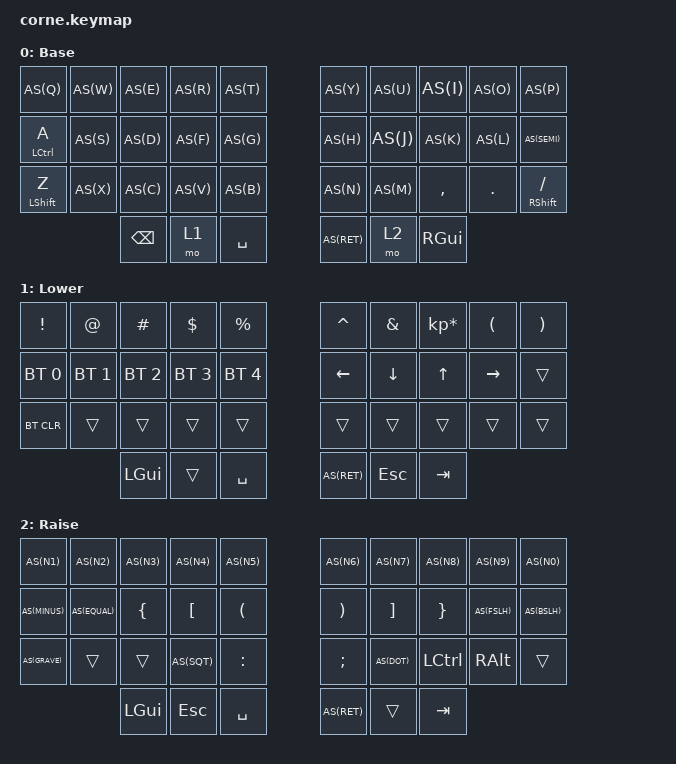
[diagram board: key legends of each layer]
/*
 * Copyright (c) 2020 The ZMK Contributors
 *
 * SPDX-License-Identifier: MIT
 */

#include <behaviors.dtsi>
#include <dt-bindings/zmk/keys.h>
#include <dt-bindings/zmk/bt.h>


#define AS(keycode) &kp keycode

/ {
    chosen {
      zmk,matrix_transform = &five_column_transform;
    };

    behaviors {
        bhm: balanced_homerow_mods {
            compatible = "zmk,behavior-hold-tap";
            #binding-cells = <2>;
            tapping-term-ms = <800>;    // <---[[moderate duration]]
            quick-tap-ms = <0>;
            flavor = "balanced";
            bindings = <&kp>, <&kp>;
        };
    };
        keymap {
                compatible = "zmk,keymap";

                default_layer {
// -----------------------------------------------------------------------------------------
// |  Q  |  W  |  E   |  R  |  T  |     |  Y  |  U   |  I   |  O   | P |
// |  A  |  S  |  D   |  F  |  G  |     |  H  |  J   |  K   |  L   | ' | 
// |  Z  |  X  |  C   |  V  |  B  |     |  N  |  M   | CTRL | META | . |
//             | BSPC | LWR | SPC |     | ENT | RSE  | GUI  |
                        display-name = "Base";
                        bindings = <
   AS(Q) AS(W) AS(E) AS(R) AS(T)     AS(Y)   AS(U)  AS(I)     AS(O)     AS(P)
   &bhm LCTRL A AS(S) AS(D) AS(F) AS(G)     AS(H)   AS(J)  AS(K)     AS(L)     AS(SEMI)
   &bhm LSHIFT Z AS(X) AS(C) AS(V) AS(B)     AS(N)   AS(M)  &kp COMMA  &kp DOT &bhm RSHIFT FSLH 
        &kp BSPC &mo 1 &kp SPACE     AS(RET) &mo 2  &kp RGUI
                        >;
                };

                lower_layer {
// -----------------------------------------------------------------------------------------
// | !     |  @  |  #  |  $  |  %  |     |  ^  |  &  |  *  |  (  |  )  |
// | BT1   | BT2 | BT3 | BT4 | BT5 |     | LFT | DWN |  UP | RGT |     |
// | BTCLR |     |     |     |     |     |     |     |     |     |     |
//               | GUI |     | SPC |     | ENT | ESC | TAB |
                        display-name = "Lower";
                        bindings = <
   &kp EXCL     &kp AT       &kp HASH     &kp DLLR     &kp PRCNT        &kp CARET &kp AMPS  &kp KP_MULTIPLY &kp LPAR  &kp RPAR
   &bt BT_SEL 0 &bt BT_SEL 1 &bt BT_SEL 2 &bt BT_SEL 3 &bt BT_SEL 4     &kp LEFT  &kp DOWN  &kp UP          &kp RIGHT &trans 
   &bt BT_CLR   &trans       &trans       &trans       &trans           &trans    &trans    &trans          &trans    &trans 
                             &kp LGUI     &trans       &kp SPACE        AS(RET)   &kp ESC   &kp TAB
                        >;
                };

                raise_layer {
// -----------------------------------------------------------------------------------------
// | 1! |  2@ |  3# |  4$ |  5% |     |  6^ |  7& |  8* |  9(  |  0)  |
// | -_ |  =+ |  {  |  [  |  (  |     |  )  |  ]  |  }  |  /?  |  \|  |
// | `~ |     |     |  '" |  :  |     |  ;  |  .> | CTRL| META |      |
//            | GUI | ESC | SPC |     | ENT |     | TAB |
                        display-name = "Raise";
                        bindings = <

   AS(N1)    AS(N2)    AS(N3)    AS(N4)    AS(N5)        AS(N6)    AS(N7)    AS(N8)    AS(N9)   AS(N0)
   AS(MINUS) AS(EQUAL) &kp LBRC  &kp LBKT  &kp LPAR      &kp RPAR  &kp RBKT  &kp RBRC  AS(FSLH) AS(BSLH)
   AS(GRAVE) &trans    &trans    AS(SQT) &kp COLON     &kp SEMI  AS(DOT)   &kp LCTRL &kp RALT &trans
                       &kp LGUI  &kp ESC   &kp SPACE     AS(RET)   &trans    &kp TAB
                        >;
                };
        };
};
